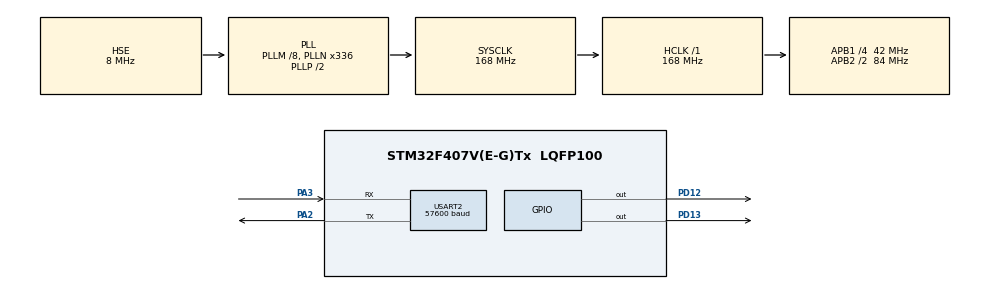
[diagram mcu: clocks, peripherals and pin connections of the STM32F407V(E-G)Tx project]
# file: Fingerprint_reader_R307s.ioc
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Mcu.Family=STM32F4
Mcu.Name=STM32F407V(E-G)Tx
Mcu.Package=LQFP100
NVIC.PriorityGroup=NVIC_PRIORITYGROUP_0
PA13.Mode=Trace_Asynchronous_SW
PA13.Signal=SYS_JTMS-SWDIO
PA14.Mode=Trace_Asynchronous_SW
PA14.Signal=SYS_JTCK-SWCLK
PA2.Mode=Asynchronous
PA2.Signal=USART2_TX
PA3.Mode=Asynchronous
PA3.Signal=USART2_RX
PB3.Mode=Trace_Asynchronous_SW
PB3.Signal=SYS_JTDO-SWO
PD12.Signal=GPIO_Output
PD13.Signal=GPIO_Output
PH0-OSC_IN.Mode=HSE-External-Oscillator
PH0-OSC_IN.Signal=RCC_OSC_IN
PH1-OSC_OUT.Mode=HSE-External-Oscillator
PH1-OSC_OUT.Signal=RCC_OSC_OUT
ProjectManager.HeapSize=0x200
ProjectManager.StackSize=0x400
ProjectManager.TargetToolchain=STM32CubeIDE
RCC.48MHZClocksFreq_Value=48000000
RCC.AHBFreq_Value=168000000
RCC.APB1CLKDivider=RCC_HCLK_DIV4
RCC.APB1Freq_Value=42000000
RCC.APB1TimFreq_Value=84000000
RCC.APB2CLKDivider=RCC_HCLK_DIV2
RCC.APB2Freq_Value=84000000
RCC.APB2TimFreq_Value=168000000
RCC.CortexFreq_Value=168000000
RCC.HCLKFreq_Value=168000000
RCC.HSE_VALUE=8000000
RCC.HSI_VALUE=16000000
RCC.LSE_VALUE=32768
RCC.PLLM=8
RCC.PLLN=336
RCC.PLLQ=7
RCC.PLLSourceVirtual=RCC_PLLSOURCE_HSE
RCC.SYSCLKFreq_VALUE=168000000
RCC.SYSCLKSource=RCC_SYSCLKSOURCE_PLLCLK
RCC.VCOOutputFreq_Value=336000000
USART2.BaudRate=57600
USART2.VirtualMode=VM_ASYNC
board=STM32F407G-DISC1

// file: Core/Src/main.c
/* USER CODE BEGIN Header */
/**
  ******************************************************************************
  * @file           : main.c
  * @brief          : Main program body
  ******************************************************************************
  * @attention
  *
  * Copyright (c) 2026 STMicroelectronics.
  * All rights reserved.
  *
  * This software is licensed under terms that can be found in the LICENSE file
  * in the root directory of this software component.
  * If no LICENSE file comes with this software, it is provided AS-IS.
  *
  ******************************************************************************
  */
/* USER CODE END Header */
#include "main.h"

/* USER CODE BEGIN Includes */
#include "stdio.h"

/* USER CODE END Includes */

UART_HandleTypeDef huart2;

/* USER CODE BEGIN PV */
HAL_StatusTypeDef ret;
/* USER CODE END PV */

void SystemClock_Config(void);
static void MX_GPIO_Init(void);
static void MX_USART2_UART_Init(void);

/* USER CODE BEGIN 0 */
void Tx(uint8_t *m,uint16_t len)
{
    HAL_UART_Transmit(&huart2,m,len,HAL_MAX_DELAY);
}
int __io_putchar(int ch) { ITM_SendChar(ch); return ch; }

void handshake_cmd(void )
{
  uint8_t Handshake[] =
  {
  0xEF,0x01, //header
  0xFF,0xFF,0xFF,0xFF, // addr
  0x01, // pid
  0x00,0x03, // len (bytes)
  0x35, // cmd
  0x00,0x39 //check sum
  };
  uint8_t rx[20];

Tx(Handshake,sizeof(Handshake));
ret = HAL_UART_Receive(&huart2,rx,12,1000);
printf("RET=%d\r\n",ret);
     if  (ret==HAL_OK)
  {
     printf(" Handshake RX : ");
       for(int i=0;i<12;i++)
    printf("%02X ",rx[i]);

      printf(" SUCCESS\r\n");
  }

   else
	printf("HANDSHAKE not working \n");
}

void fp_capture(void )
{
  uint8_t getImage_cmd[] =
  {
      0xEF,0x01, //head
      0xFF,0xFF,0xFF,0xFF, // addr
      0x01, //pid
      0x00,0x03,  //  len
      0x01, // cmd
      0x00,0x05
  };
  uint8_t rx[20];

  printf("put Finger\r\n");
HAL_Delay(2500);
  Tx(getImage_cmd, sizeof(getImage_cmd));
  printf("rmve Finger\r\n");

  ret = HAL_UART_Receive(&huart2, rx, 12, 1000);

  if(ret==HAL_OK)
  {
      printf("fp_capture RX : ");

      for(int i=0;i<12;i++)
          printf("%02X ",rx[i]);

      printf("\rCaptured!!!\r\n");
  }
  else
	  printf("capture failed\n");
}

void imgtocharbuff1(void)
{
  uint8_t genchar[] =
  {
      0xEF,0x01, //header
      0xFF,0xFF,0xFF,0xFF, //addr
      0x01, // pid
      0x00,0x04, //len
      0x02,0x01, // cmd & buffer id
      0x00,0x08 //cheksum
  };
  uint8_t rx[20];

  Tx(genchar, sizeof(genchar));
  ret = HAL_UART_Receive(&huart2, rx, 12, 1000);
  if(ret==HAL_OK)
    {
        printf("imgtocharbuff1 : ");

        for(int i=0;i<12;i++)
            printf("%02X ",rx[i]);

        printf("\r\n");
    }
  else
	  printf("character file failed\n");

}

void imgtocharbuff2(void)
 {uint8_t genchar2[] =
  {
      0xEF,0x01, //header
      0xFF,0xFF,0xFF,0xFF, //addr
      0x01, // pid
      0x00,0x04, //len
      0x02,0x02, // cmd & buffer id
      0x00,0x09 //cheksum
  };
 uint8_t rx[20];

  Tx(genchar2, sizeof(genchar2));
  ret = HAL_UART_Receive(&huart2, rx, 12, 1000);
  if(ret==HAL_OK)
    {
        printf("imgtocharbuff2 RX : ");

        for(int i=0;i<12;i++)
            printf("%02X ",rx[i]);

        printf("\r\n");
    }
  HAL_Delay(50);
 }
void template_generation (void){
		uint8_t regmodel[] =
  {
      0xEF,0x01, //header
      0xFF,0xFF,0xFF,0xFF, //addr
      0x01, // pid
      0x00,0x03, //len
      0x05, // cmd
      0x00,0x09 //cheksum
  };
		uint8_t rx[20];

  Tx(regmodel, sizeof(regmodel));
  ret = HAL_UART_Receive(&huart2, rx, 12, 1000);
  if(ret==HAL_OK)
    {
        printf("Merge RX : ");

        for(int i=0;i<12;i++)
            printf("%02X ",rx[i]);

        printf("\r\n");
        printf("stored\r\n");

    }
}

void template_store(uint8_t bufid ,int8_t chk ,int8_t ids){
	 uint8_t id []=
 {
     0xEF,0x01, //header
     0xFF,0xFF,0xFF,0xFF, //addr
     0x01, // pid
     0x00,0x06, //len
     0x06,bufid, // cmd & buffer id
	  0x00,ids,  // mem loc id (2 bytes)
     0x00,chk   //cheksum
 };
 uint8_t rx[20];

 Tx(id, sizeof(id));
 ret = HAL_UART_Receive(&huart2, rx, 12, 1000);
 if(ret==HAL_OK)
   {
       printf("RX : ");

       for(int i=0;i<12;i++)
           printf("%02X ",rx[i]);

       printf("\r\n");
   }
 printf("stored\r\n");

}

void search(void){

uint8_t user []=
	   {
	       0xEF,0x01, //header
	       0xFF,0xFF,0xFF,0xFF, //addr
	       0x01, // pid
	       0x00,0x08,
		   //len
	       0x04,0x01, // cmd & buffer id
	 	  0x00,0x01,  // st pge(2 bytes)
	 	  0x00,0x02,  // pge num (2 bytes)
	       0x00,0x11 //cheksum
	   };
uint8_t rx[40];
	   Tx(user, sizeof(user));
	   ret = HAL_UART_Receive(&huart2, rx, 16, 1000);
	   if(ret==HAL_OK)
	     {
	         printf("last RX : ");

	         for(int i=0;i<16;i++)
	             printf("%02X ",rx[i]);

	         if (rx[9]== 0x00){
                  printf("MATCHEDDDDDDDDDDDDDD\n");
HAL_GPIO_WritePin(GPIOD, GPIO_PIN_12, SET);
	         }

	         else
	        	 printf("\nnotttttttttttttttttttttt\n");

 }

}

volatile int c=0;

 void HAL_GPIO_EXTI_Callback(uint16_t GPIO_Pin){
	 if (HAL_GPIO_ReadPin(GPIOA, GPIO_PIN_1) == GPIO_PIN_RESET)
		 c =1;
 }

/* USER CODE END 0 */

int main(void)
{

  /* MCU Configuration--------------------------------------------------------*/

  /* Reset of all peripherals, Initializes the Flash interface and the Systick. */
  HAL_Init();

  /* Configure the system clock */
  SystemClock_Config();

  /* Initialize all configured peripherals */
  MX_GPIO_Init();
  MX_USART2_UART_Init();
  /* USER CODE BEGIN 2 */
  printf("printf works\n ");

  handshake_cmd();

// #1
  fp_capture();
  imgtocharbuff1();
  fp_capture( );
  imgtocharbuff2();
  template_generation();
  template_store(0x01 ,0x0F ,0x01);

//  #2
HAL_Delay(2000);
  fp_capture();
    imgtocharbuff1();
    fp_capture( );
    imgtocharbuff2();
    template_generation();
    template_store(0x01, 0x10, 0x02);

    //  uint8_t getImage2_cmd[] =
//  {
//      0xEF,0x01,
//      0xFF,0xFF,0xFF,0xFF,
//      0x01,
//      0x00,0x03,
//      0x01,
//      0x00,0x05
//  };
//  uint8_t rx[20];
//
//  Tx(getImage2_cmd, sizeof(getImage2_cmd));
//
//  ret = HAL_UART_Receive(&huart2, rx, 12, 1000);
//
//  if(ret==HAL_OK)
//  {
//      printf("RX : ");
//
//      for(int i=0;i<12;i++)
//          printf("%02X ",rx[i]);
//
//      printf("\r\n");
//  }
//  printf("remove   Finger\r\n");
//  HAL_Delay(3000);

// generating data from img

//// storing

//// id

  /* USER CODE END 2 */

  /* Infinite loop */
  while (1)
  {

    /* USER CODE BEGIN 3 */
if(1){
	HAL_GPIO_WritePin(GPIOD, GPIO_PIN_12, RESET);

	  printf("search\n");
	  fp_capture( );
	  imgtocharbuff1();
	  search();
	  HAL_Delay(2000);
	  c=0;

}

//	  uint8_t getImage3_cmd[] =
//	   {
//	       0xEF,0x01,
//	       0xFF,0xFF,0xFF,0xFF,
//	       0x01,
//	       0x00,0x03,
//	       0x01,
//	       0x00,0x05
//	   };
//
//	   Tx(getImage3_cmd, sizeof(getImage3_cmd));
//
//	   ret = HAL_UART_Receive(&huart2, rx, 12, 1000);
//
//	   if(ret==HAL_OK)
//	   {
//	       printf("img capture RX : ");
//
//	       for(int i=0;i<12;i++)
//	           printf("%02X ",rx[i]);
//
//	       printf("\r\n");
//	   }
//	   printf("remove   Finger\r\n");

	 // generating data from img
//	   uint8_t genchar3[] =
//	   {
//	       0xEF,0x01, //header
//	       0xFF,0xFF,0xFF,0xFF, //addr
//	       0x01, // pid
//	       0x00,0x04, //len
//	       0x02,0x01, // cmd & buffer id
//	       0x00,0x09 //cheksum
//	   };
//	   Tx(genchar3, sizeof(genchar3));
//	   ret = HAL_UART_Receive(&huart2, rx, 12, 1000);
//	   if(ret==HAL_OK)
//	     {
//	         printf("RX : ");
//
//	         for(int i=0;i<12;i++)
//	             printf("%02X ",rx[i]);
//
//	         printf("\r\n");
//	     }
//	   HAL_Delay(50);

  }
  /* USER CODE END 3 */
}

void SystemClock_Config(void)
{
  RCC_OscInitTypeDef RCC_OscInitStruct = {0};
  RCC_ClkInitTypeDef RCC_ClkInitStruct = {0};

  /** Configure the main internal regulator output voltage
  */
  __HAL_RCC_PWR_CLK_ENABLE();
  __HAL_PWR_VOLTAGESCALING_CONFIG(PWR_REGULATOR_VOLTAGE_SCALE1);

  /** Initializes the RCC Oscillators according to the specified parameters
  * in the RCC_OscInitTypeDef structure.
  */
  RCC_OscInitStruct.OscillatorType = RCC_OSCILLATORTYPE_HSE;
  RCC_OscInitStruct.HSEState = RCC_HSE_ON;
  RCC_OscInitStruct.PLL.PLLState = RCC_PLL_ON;
  RCC_OscInitStruct.PLL.PLLSource = RCC_PLLSOURCE_HSE;
  RCC_OscInitStruct.PLL.PLLM = 8;
  RCC_OscInitStruct.PLL.PLLN = 336;
  RCC_OscInitStruct.PLL.PLLP = RCC_PLLP_DIV2;
  RCC_OscInitStruct.PLL.PLLQ = 7;
  if (HAL_RCC_OscConfig(&RCC_OscInitStruct) != HAL_OK)
  {
    Error_Handler();
  }

  /** Initializes the CPU, AHB and APB buses clocks
  */
  RCC_ClkInitStruct.ClockType = RCC_CLOCKTYPE_HCLK|RCC_CLOCKTYPE_SYSCLK
                              |RCC_CLOCKTYPE_PCLK1|RCC_CLOCKTYPE_PCLK2;
  RCC_ClkInitStruct.SYSCLKSource = RCC_SYSCLKSOURCE_PLLCLK;
  RCC_ClkInitStruct.AHBCLKDivider = RCC_SYSCLK_DIV1;
  RCC_ClkInitStruct.APB1CLKDivider = RCC_HCLK_DIV4;
  RCC_ClkInitStruct.APB2CLKDivider = RCC_HCLK_DIV2;

  if (HAL_RCC_ClockConfig(&RCC_ClkInitStruct, FLASH_LATENCY_5) != HAL_OK)
  {
    Error_Handler();
  }
}

static void MX_USART2_UART_Init(void)
{

  huart2.Instance = USART2;
  huart2.Init.BaudRate = 57600;
  huart2.Init.WordLength = UART_WORDLENGTH_8B;
  huart2.Init.StopBits = UART_STOPBITS_1;
  huart2.Init.Parity = UART_PARITY_NONE;
  huart2.Init.Mode = UART_MODE_TX_RX;
  huart2.Init.HwFlowCtl = UART_HWCONTROL_NONE;
  huart2.Init.OverSampling = UART_OVERSAMPLING_16;
  if (HAL_UART_Init(&huart2) != HAL_OK)
  {
    Error_Handler();
  }

}

static void MX_GPIO_Init(void)
{
  GPIO_InitTypeDef GPIO_InitStruct = {0};

  /* GPIO Ports Clock Enable */
  __HAL_RCC_GPIOH_CLK_ENABLE();
  __HAL_RCC_GPIOA_CLK_ENABLE();
  __HAL_RCC_GPIOD_CLK_ENABLE();
  __HAL_RCC_GPIOB_CLK_ENABLE();

  /*Configure GPIO pin Output Level */
  HAL_GPIO_WritePin(GPIOD, GPIO_PIN_12|GPIO_PIN_13, GPIO_PIN_RESET);

  /*Configure GPIO pin : PA1 */
  GPIO_InitStruct.Pin = GPIO_PIN_1;
  GPIO_InitStruct.Mode = GPIO_MODE_IT_FALLING;
  GPIO_InitStruct.Pull = GPIO_PULLUP;
  HAL_GPIO_Init(GPIOA, &GPIO_InitStruct);

  /*Configure GPIO pins : PD12 PD13 */
  GPIO_InitStruct.Pin = GPIO_PIN_12|GPIO_PIN_13;
  GPIO_InitStruct.Mode = GPIO_MODE_OUTPUT_PP;
  GPIO_InitStruct.Pull = GPIO_NOPULL;
  GPIO_InitStruct.Speed = GPIO_SPEED_FREQ_LOW;
  HAL_GPIO_Init(GPIOD, &GPIO_InitStruct);

  /* EXTI interrupt init*/
  HAL_NVIC_SetPriority(EXTI1_IRQn, 0, 0);
  HAL_NVIC_EnableIRQ(EXTI1_IRQn);

}

void Error_Handler(void)
{
  __disable_irq();
  while (1)
  {
  }
}
